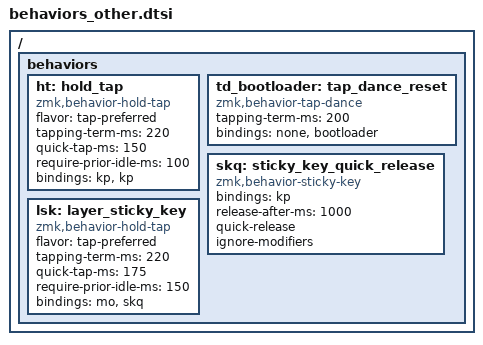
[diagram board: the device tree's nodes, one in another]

/ {

   behaviors {

        ht: hold_tap {
            compatible = "zmk,behavior-hold-tap";
            #binding-cells = <2>;
            flavor = "tap-preferred";
            tapping-term-ms = <220>;
            quick-tap-ms = <150>;
            require-prior-idle-ms = <100>;
            bindings = <&kp>, <&kp>;
        };

        td_bootloader: tap_dance_reset {
            compatible = "zmk,behavior-tap-dance";
            #binding-cells = <0>;
            tapping-term-ms = <200>;
            bindings = <&none>, <&bootloader>;
        };

        skq: sticky_key_quick_release {
            compatible = "zmk,behavior-sticky-key";
            #binding-cells = <1>;
            bindings = <&kp>;
            release-after-ms = <1000>;
            quick-release;
            ignore-modifiers;
        };


        lsk: layer_sticky_key {
            compatible = "zmk,behavior-hold-tap";
            #binding-cells = <2>;
            flavor = "tap-preferred";
            tapping-term-ms = <220>;
            quick-tap-ms = <175>;
            require-prior-idle-ms = <150>;
            bindings = <&mo>, <&skq>;
        };
     };
  };

